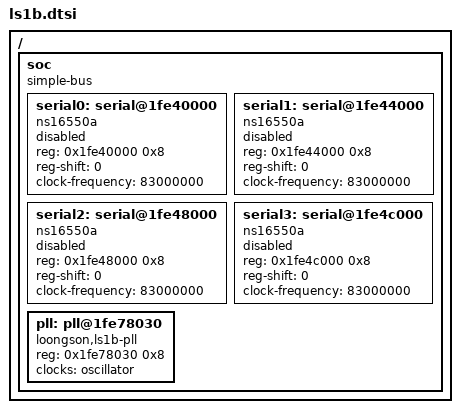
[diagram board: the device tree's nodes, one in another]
#include <dt-bindings/clock/ls1b-clk.h>

/ {
	#address-cells = <1>;
	#size-cells = <1>;

	soc {
		#address-cells = <1>;
		#size-cells = <1>;
		compatible = "simple-bus";
		device_type = "soc";
		ranges;

		serial0: serial@1fe40000 {
			compatible = "ns16550a";
			reg = <0x1fe40000 0x8>;
			reg-shift = <0>;
			clock-frequency = <83000000>;
			status = "disabled";
		};

		serial1: serial@1fe44000 {
			compatible = "ns16550a";
			reg = <0x1fe44000 0x8>;
			reg-shift = <0>;
			clock-frequency = <83000000>;
			status = "disabled";
		};

		serial2: serial@1fe48000 {
			compatible = "ns16550a";
			reg = <0x1fe48000 0x8>;
			reg-shift = <0>;
			clock-frequency = <83000000>;
			status = "disabled";
		};

		serial3: serial@1fe4c000 {
			compatible = "ns16550a";
			reg = <0x1fe4c000 0x8>;
			reg-shift = <0>;
			clock-frequency = <83000000>;
			status = "disabled";
		};

		pll: pll@1fe78030 {
			compatible = "loongson,ls1b-pll";
			#clock-cells = <1>;
			reg = <0x1fe78030 0x8>;
			clocks = <&oscillator>;
		};
	};
};
